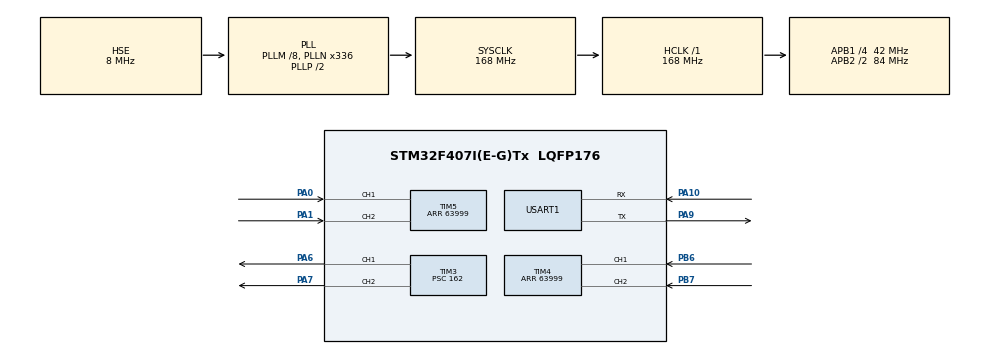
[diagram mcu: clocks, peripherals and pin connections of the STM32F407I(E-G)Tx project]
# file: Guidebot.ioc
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Dma.Request0=USART1_RX
Dma.Request1=USART1_TX
Dma.USART1_RX.0.Direction=DMA_PERIPH_TO_MEMORY
Dma.USART1_RX.0.FIFOMode=DMA_FIFOMODE_DISABLE
Dma.USART1_RX.0.Instance=DMA2_Stream2
Dma.USART1_RX.0.MemDataAlignment=DMA_MDATAALIGN_BYTE
Dma.USART1_RX.0.MemInc=DMA_MINC_ENABLE
Dma.USART1_RX.0.Mode=DMA_CIRCULAR
Dma.USART1_RX.0.PeriphDataAlignment=DMA_PDATAALIGN_BYTE
Dma.USART1_RX.0.PeriphInc=DMA_PINC_DISABLE
Dma.USART1_RX.0.Priority=DMA_PRIORITY_VERY_HIGH
Dma.USART1_TX.1.Direction=DMA_MEMORY_TO_PERIPH
Dma.USART1_TX.1.FIFOMode=DMA_FIFOMODE_DISABLE
Dma.USART1_TX.1.Instance=DMA2_Stream7
Dma.USART1_TX.1.MemDataAlignment=DMA_MDATAALIGN_BYTE
Dma.USART1_TX.1.MemInc=DMA_MINC_ENABLE
Dma.USART1_TX.1.Mode=DMA_NORMAL
Dma.USART1_TX.1.PeriphDataAlignment=DMA_PDATAALIGN_BYTE
Dma.USART1_TX.1.PeriphInc=DMA_PINC_DISABLE
Dma.USART1_TX.1.Priority=DMA_PRIORITY_HIGH
Mcu.Family=STM32F4
Mcu.Name=STM32F407I(E-G)Tx
Mcu.Package=LQFP176
NVIC.DMA2_Stream2_IRQn=true\:0\:0\:false\:false\:true\:false\:true
NVIC.DMA2_Stream7_IRQn=true\:0\:0\:false\:false\:true\:false\:true
NVIC.PriorityGroup=NVIC_PRIORITYGROUP_4
NVIC.TIM3_IRQn=true\:0\:0\:false\:false\:true\:true\:true
NVIC.TIM4_IRQn=true\:2\:0\:true\:false\:true\:true\:true
NVIC.TIM5_IRQn=true\:2\:0\:true\:false\:true\:true\:true
NVIC.USART1_IRQn=true\:0\:0\:true\:false\:true\:true\:true
PA0-WKUP.GPIO_ModeDefaultPP=GPIO_MODE_AF_PP
PA0-WKUP.GPIO_PuPd=GPIO_PULLUP
PA0-WKUP.GPIO_Speed=GPIO_SPEED_FREQ_VERY_HIGH
PA0-WKUP.Signal=S_TIM5_CH1
PA1.GPIO_PuPd=GPIO_PULLUP
PA1.GPIO_Speed=GPIO_SPEED_FREQ_VERY_HIGH
PA1.Signal=S_TIM5_CH2
PA10.GPIO_Speed=GPIO_SPEED_FREQ_HIGH
PA10.Mode=Asynchronous
PA10.Signal=USART1_RX
PA13.Mode=Serial_Wire
PA13.Signal=SYS_JTMS-SWDIO
PA14.Mode=Serial_Wire
PA14.Signal=SYS_JTCK-SWCLK
PA6.Signal=S_TIM3_CH1
PA7.Signal=S_TIM3_CH2
PA9.GPIO_Speed=GPIO_SPEED_FREQ_HIGH
PA9.Mode=Asynchronous
PA9.Signal=USART1_TX
PB6.GPIO_PuPd=GPIO_PULLUP
PB6.GPIO_Speed=GPIO_SPEED_FREQ_VERY_HIGH
PB6.Signal=S_TIM4_CH1
PB7.GPIO_PuPd=GPIO_PULLUP
PB7.GPIO_Speed=GPIO_SPEED_FREQ_VERY_HIGH
PB7.Signal=S_TIM4_CH2
PH0-OSC_IN.Mode=HSE-External-Oscillator
PH0-OSC_IN.Signal=RCC_OSC_IN
PH1-OSC_OUT.Mode=HSE-External-Oscillator
PH1-OSC_OUT.Signal=RCC_OSC_OUT
ProjectManager.HeapSize=0x200
ProjectManager.StackSize=0x400
ProjectManager.TargetToolchain=MDK-ARM V5
RCC.48MHZClocksFreq_Value=84000000
RCC.AHBFreq_Value=168000000
RCC.APB1CLKDivider=RCC_HCLK_DIV4
RCC.APB1Freq_Value=42000000
RCC.APB1TimFreq_Value=84000000
RCC.APB2CLKDivider=RCC_HCLK_DIV2
RCC.APB2Freq_Value=84000000
RCC.APB2TimFreq_Value=168000000
RCC.CortexFreq_Value=168000000
RCC.HCLKFreq_Value=168000000
RCC.HSE_VALUE=8000000
RCC.HSI_VALUE=16000000
RCC.LSE_VALUE=32768
RCC.PLLM=8
RCC.PLLN=336
RCC.PLLSourceVirtual=RCC_PLLSOURCE_HSE
RCC.SYSCLKFreq_VALUE=168000000
RCC.SYSCLKSource=RCC_SYSCLKSOURCE_PLLCLK
RCC.VCOOutputFreq_Value=336000000
SH.S_TIM3_CH1.0=TIM3_CH1,PWM Generation1 CH1
SH.S_TIM3_CH2.0=TIM3_CH2,PWM Generation2 CH2
SH.S_TIM4_CH1.0=TIM4_CH1,Encoder_Interface
SH.S_TIM4_CH2.0=TIM4_CH2,Encoder_Interface
SH.S_TIM5_CH1.0=TIM5_CH1,Encoder_Interface
SH.S_TIM5_CH2.0=TIM5_CH2,Encoder_Interface
TIM2.Period=0xffffffff
TIM2.Prescaler=42000-1
TIM3.AutoReloadPreload=TIM_AUTORELOAD_PRELOAD_ENABLE
TIM3.Channel-PWM\ Generation1\ CH1=TIM_CHANNEL_1
TIM3.Channel-PWM\ Generation2\ CH2=TIM_CHANNEL_2
TIM3.OCMode_PWM-PWM\ Generation1\ CH1=TIM_OCMODE_PWM2
TIM3.OCMode_PWM-PWM\ Generation2\ CH2=TIM_OCMODE_PWM2
TIM3.OCPolarity_1=TIM_OCPOLARITY_LOW
TIM3.OCPolarity_2=TIM_OCPOLARITY_LOW
TIM3.Period=1999
TIM3.Prescaler=162
TIM4.EncoderMode=TIM_ENCODERMODE_TI12
TIM4.IC1Polarity=TIM_ICPOLARITY_RISING
TIM4.IC2Polarity=TIM_ICPOLARITY_RISING
TIM4.Period=63999
TIM5.Period=63999
USART1.VirtualMode=VM_ASYNC
VP_TIM2_VS_ClockSourceINT.Mode=Internal
VP_TIM3_VS_ClockSourceINT.Mode=Internal
board=custom

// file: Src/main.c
/* USER CODE BEGIN Header */
/**
  ******************************************************************************
  * @file           : main.c
  * @brief          : Main program body
  ******************************************************************************
  * @attention
  *
  * <h2><center>&copy; Copyright (c) 2019 STMicroelectronics.
  * All rights reserved.</center></h2>
  *
  * This software component is licensed by ST under BSD 3-Clause license,
  * the "License"; You may not use this file except in compliance with the
  * License. You may obtain a copy of the License at:
  *                        opensource.org/licenses/BSD-3-Clause
  *
  ******************************************************************************
  */
/* USER CODE END Header */

#include "main.h"
#include "dma.h"
#include "tim.h"
#include "usart.h"
#include "gpio.h"

/* USER CODE BEGIN Includes */
#include "mainpp.h"
/* USER CODE END Includes */

void SystemClock_Config(void);

int main(void)
{

  /* MCU Configuration--------------------------------------------------------*/

  /* Reset of all peripherals, Initializes the Flash interface and the Systick. */
  HAL_Init();

  /* Configure the system clock */
  SystemClock_Config();

  /* Initialize all configured peripherals */
  MX_GPIO_Init();
  MX_DMA_Init();
  MX_TIM2_Init();
  MX_USART1_UART_Init();
  MX_TIM3_Init();
  MX_TIM4_Init();
  MX_TIM5_Init();
  /* USER CODE BEGIN 2 */
  HAL_TIM_Base_Start(&htim2);
  HAL_TIM_Base_Start(&htim3);
  HAL_TIM_Base_Start(&htim4);
  HAL_TIM_Base_Start(&htim5);
  HAL_TIM_PWM_Start(&htim3, TIM_CHANNEL_1);
  HAL_TIM_PWM_Start(&htim3, TIM_CHANNEL_2);
  HAL_TIM_Encoder_Start(&htim4, TIM_CHANNEL_ALL);
  HAL_TIM_Encoder_Start(&htim5, TIM_CHANNEL_ALL);

  setup();
  /* USER CODE END 2 */

  /* Infinite loop */
  /* USER CODE BEGIN WHILE */
  while (1)
  {
    loop();
    /* USER CODE END WHILE */

  }
}

void SystemClock_Config(void)
{
  RCC_OscInitTypeDef RCC_OscInitStruct = {0};
  RCC_ClkInitTypeDef RCC_ClkInitStruct = {0};

  /** Configure the main internal regulator output voltage
  */
  __HAL_RCC_PWR_CLK_ENABLE();
  __HAL_PWR_VOLTAGESCALING_CONFIG(PWR_REGULATOR_VOLTAGE_SCALE1);
  /** Initializes the CPU, AHB and APB busses clocks
  */
  RCC_OscInitStruct.OscillatorType = RCC_OSCILLATORTYPE_HSE;
  RCC_OscInitStruct.HSEState = RCC_HSE_ON;
  RCC_OscInitStruct.PLL.PLLState = RCC_PLL_ON;
  RCC_OscInitStruct.PLL.PLLSource = RCC_PLLSOURCE_HSE;
  RCC_OscInitStruct.PLL.PLLM = 8;
  RCC_OscInitStruct.PLL.PLLN = 336;
  RCC_OscInitStruct.PLL.PLLP = RCC_PLLP_DIV2;
  RCC_OscInitStruct.PLL.PLLQ = 4;
  if (HAL_RCC_OscConfig(&RCC_OscInitStruct) != HAL_OK)
  {
    Error_Handler();
  }
  /** Initializes the CPU, AHB and APB busses clocks
  */
  RCC_ClkInitStruct.ClockType = RCC_CLOCKTYPE_HCLK|RCC_CLOCKTYPE_SYSCLK
                              |RCC_CLOCKTYPE_PCLK1|RCC_CLOCKTYPE_PCLK2;
  RCC_ClkInitStruct.SYSCLKSource = RCC_SYSCLKSOURCE_PLLCLK;
  RCC_ClkInitStruct.AHBCLKDivider = RCC_SYSCLK_DIV1;
  RCC_ClkInitStruct.APB1CLKDivider = RCC_HCLK_DIV4;
  RCC_ClkInitStruct.APB2CLKDivider = RCC_HCLK_DIV2;

  if (HAL_RCC_ClockConfig(&RCC_ClkInitStruct, FLASH_LATENCY_5) != HAL_OK)
  {
    Error_Handler();
  }
}

void Error_Handler(void)
{
}

/************************ (C) COPYRIGHT STMicroelectronics *****END OF FILE****/
